VERSION "0.1"

NS_ :

BS_:

BU_: Broadcast CockpitECU HydrogenECU HighPowerECU SensorsECU CoolingECU IsolationECU DriverInterfaceHAT TelemetryLTEHAT

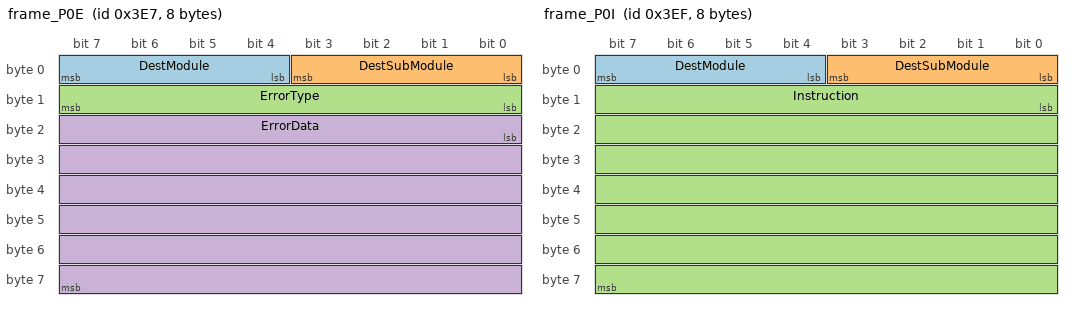
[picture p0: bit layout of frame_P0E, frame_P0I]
BO_ 999 frame_P0E: 8 Broadcast
	SG_ DestModule : 4|4@1+ (1,0) [0|0] "" Vector__XXX
	SG_ DestSubModule : 0|4@1+ (1,0) [0|0] "" Vector__XXX
	SG_ ErrorType : 8|8@1+ (1,0) [0|0] "" Vector__XXX
	SG_ ErrorData : 16|48@1+ (1,0) [0|0] "" Vector__XXX

BO_ 1007 frame_P0I: 8 Broadcast
	SG_ DestModule : 4|4@1+ (1,0) [0|0] "" Vector__XXX
	SG_ DestSubModule : 0|4@1+ (1,0) [0|0] "" Vector__XXX
	SG_ Instruction : 8|56@1+ (1,0) [0|0] "" Vector__XXX

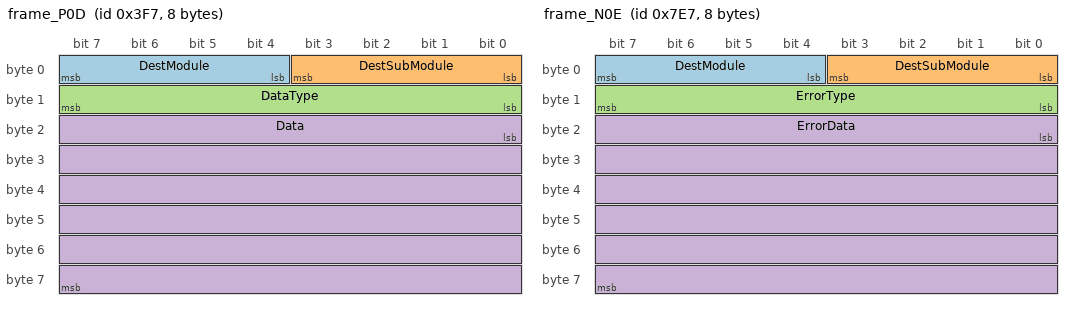
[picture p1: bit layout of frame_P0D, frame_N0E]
BO_ 1015 frame_P0D: 8 Broadcast
	SG_ DestModule : 4|4@1+ (1,0) [0|0] "" Vector__XXX
	SG_ DestSubModule : 0|4@1+ (1,0) [0|0] "" Vector__XXX
	SG_ DataType : 8|8@1+ (1,0) [0|0] "" Vector__XXX
	SG_ Data : 16|48@1+ (1,0) [0|0] "" Vector__XXX

BO_ 2023 frame_N0E: 8 Broadcast
	SG_ DestModule : 4|4@1+ (1,0) [0|0] "" Vector__XXX
	SG_ DestSubModule : 0|4@1+ (1,0) [0|0] "" Vector__XXX
	SG_ ErrorType : 8|8@1+ (1,0) [0|0] "" Vector__XXX
	SG_ ErrorData : 16|48@1+ (1,0) [0|0] "" Vector__XXX

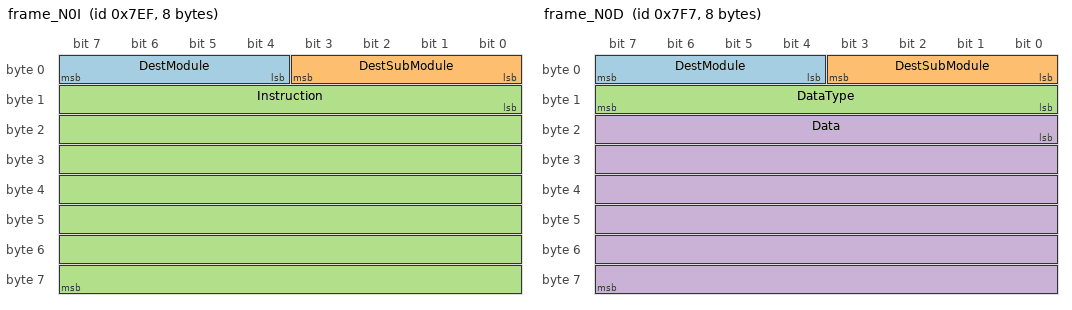
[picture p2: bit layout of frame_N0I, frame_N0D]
BO_ 2031 frame_N0I: 8 Broadcast
	SG_ DestModule : 4|4@1+ (1,0) [0|0] "" Vector__XXX
	SG_ DestSubModule : 0|4@1+ (1,0) [0|0] "" Vector__XXX
	SG_ Instruction : 8|56@1+ (1,0) [0|0] "" Vector__XXX

BO_ 2039 frame_N0D: 8 Broadcast
	SG_ DestModule : 4|4@1+ (1,0) [0|0] "" Vector__XXX
	SG_ DestSubModule : 0|4@1+ (1,0) [0|0] "" Vector__XXX
	SG_ DataType : 8|8@1+ (1,0) [0|0] "" Vector__XXX
	SG_ Data : 16|48@1+ (1,0) [0|0] "" Vector__XXX

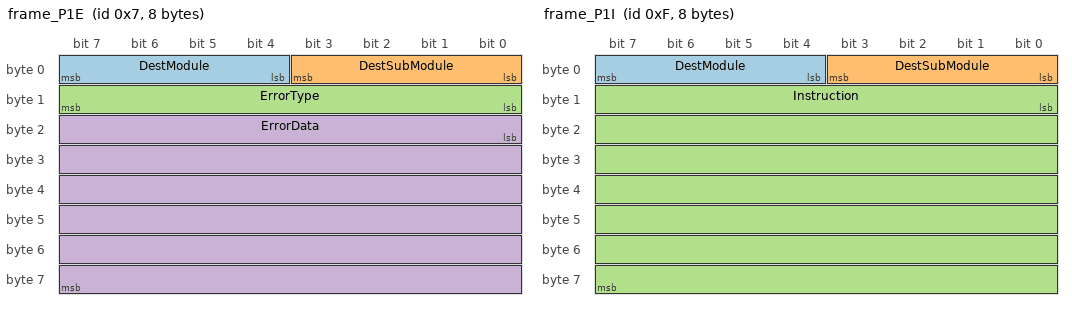
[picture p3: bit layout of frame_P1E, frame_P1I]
BO_ 7 frame_P1E: 8 CockpitECU
	SG_ DestModule : 4|4@1+ (1,0) [0|0] "" Vector__XXX
	SG_ DestSubModule : 0|4@1+ (1,0) [0|0] "" Vector__XXX
	SG_ ErrorType : 8|8@1+ (1,0) [0|0] "" Vector__XXX
	SG_ ErrorData : 16|48@1+ (1,0) [0|0] "" Vector__XXX

BO_ 15 frame_P1I: 8 CockpitECU
	SG_ DestModule : 4|4@1+ (1,0) [0|0] "" Vector__XXX
	SG_ DestSubModule : 0|4@1+ (1,0) [0|0] "" Vector__XXX
	SG_ Instruction : 8|56@1+ (1,0) [0|0] "" Vector__XXX

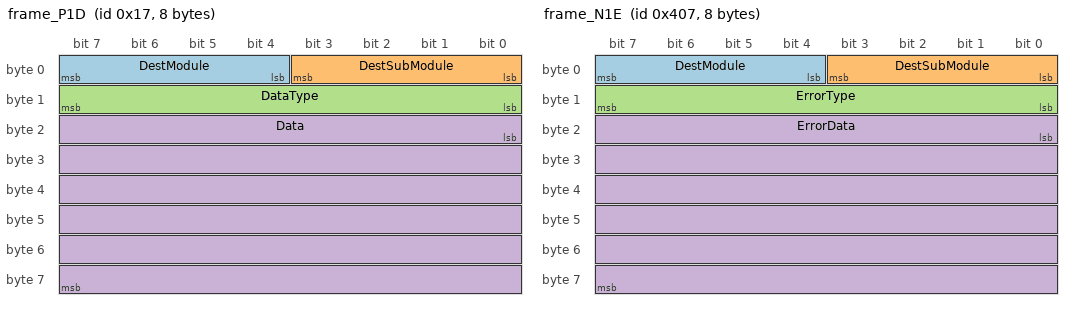
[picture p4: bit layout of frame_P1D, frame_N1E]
BO_ 23 frame_P1D: 8 CockpitECU
	SG_ DestModule : 4|4@1+ (1,0) [0|0] "" Vector__XXX
	SG_ DestSubModule : 0|4@1+ (1,0) [0|0] "" Vector__XXX
	SG_ DataType : 8|8@1+ (1,0) [0|0] "" Vector__XXX
	SG_ Data : 16|48@1+ (1,0) [0|0] "" Vector__XXX

BO_ 1031 frame_N1E: 8 CockpitECU
	SG_ DestModule : 4|4@1+ (1,0) [0|0] "" Vector__XXX
	SG_ DestSubModule : 0|4@1+ (1,0) [0|0] "" Vector__XXX
	SG_ ErrorType : 8|8@1+ (1,0) [0|0] "" Vector__XXX
	SG_ ErrorData : 16|48@1+ (1,0) [0|0] "" Vector__XXX

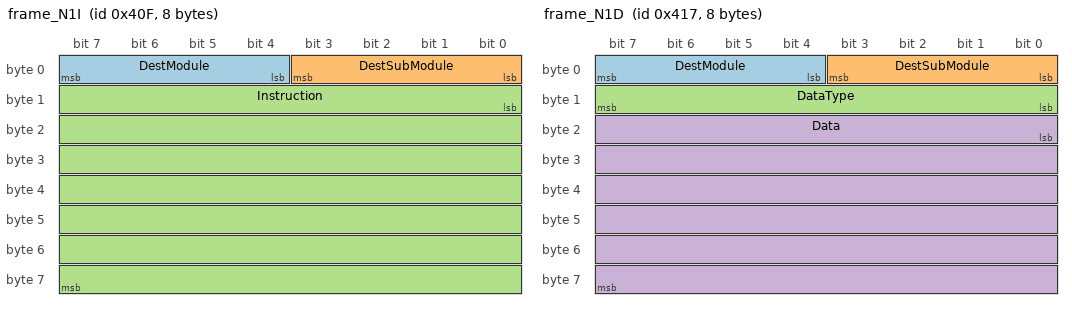
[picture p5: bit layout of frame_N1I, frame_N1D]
BO_ 1039 frame_N1I: 8 CockpitECU
	SG_ DestModule : 4|4@1+ (1,0) [0|0] "" Vector__XXX
	SG_ DestSubModule : 0|4@1+ (1,0) [0|0] "" Vector__XXX
	SG_ Instruction : 8|56@1+ (1,0) [0|0] "" Vector__XXX

BO_ 1047 frame_N1D: 8 CockpitECU
	SG_ DestModule : 4|4@1+ (1,0) [0|0] "" Vector__XXX
	SG_ DestSubModule : 0|4@1+ (1,0) [0|0] "" Vector__XXX
	SG_ DataType : 8|8@1+ (1,0) [0|0] "" Vector__XXX
	SG_ Data : 16|48@1+ (1,0) [0|0] "" Vector__XXX

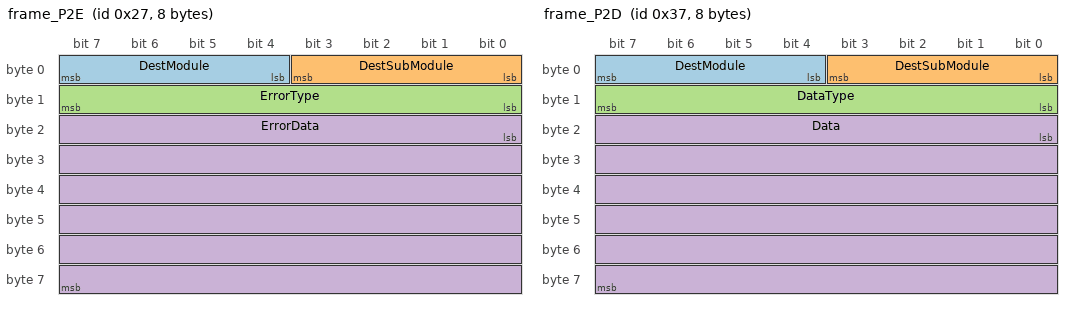
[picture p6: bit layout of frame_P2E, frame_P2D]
BO_ 39 frame_P2E: 8 HydrogenECU
	SG_ DestModule : 4|4@1+ (1,0) [0|0] "" Vector__XXX
	SG_ DestSubModule : 0|4@1+ (1,0) [0|0] "" Vector__XXX
	SG_ ErrorType : 8|8@1+ (1,0) [0|0] "" Vector__XXX
	SG_ ErrorData : 16|48@1+ (1,0) [0|0] "" Vector__XXX

BO_ 47 frame_P2I: 8 HydrogenECU
	SG_ DestModule : 4|4@1+ (1,0) [0|0] "" Vector__XXX
	SG_ DestSubModule : 0|4@1+ (1,0) [0|0] "" Vector__XXX
	SG_ Instruction : 8|56@1+ (1,0) [0|0] "" Vector__XXX

BO_ 55 frame_P2D: 8 HydrogenECU
	SG_ DestModule : 4|4@1+ (1,0) [0|0] "" Vector__XXX
	SG_ DestSubModule : 0|4@1+ (1,0) [0|0] "" Vector__XXX
	SG_ DataType : 8|8@1+ (1,0) [0|0] "" Vector__XXX
	SG_ Data : 16|48@1+ (1,0) [0|0] "" Vector__XXX

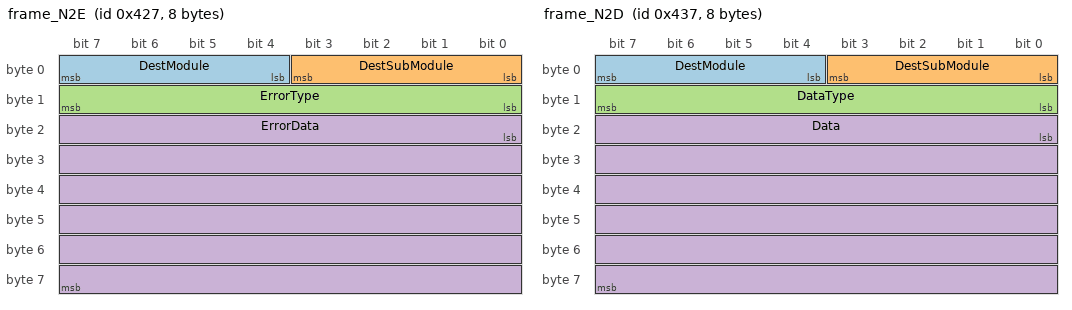
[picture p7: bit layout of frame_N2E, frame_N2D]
BO_ 1063 frame_N2E: 8 HydrogenECU
	SG_ DestModule : 4|4@1+ (1,0) [0|0] "" Vector__XXX
	SG_ DestSubModule : 0|4@1+ (1,0) [0|0] "" Vector__XXX
	SG_ ErrorType : 8|8@1+ (1,0) [0|0] "" Vector__XXX
	SG_ ErrorData : 16|48@1+ (1,0) [0|0] "" Vector__XXX

BO_ 1071 frame_N2I: 8 HydrogenECU
	SG_ DestModule : 4|4@1+ (1,0) [0|0] "" Vector__XXX
	SG_ DestSubModule : 0|4@1+ (1,0) [0|0] "" Vector__XXX
	SG_ Instruction : 8|56@1+ (1,0) [0|0] "" Vector__XXX

BO_ 1079 frame_N2D: 8 HydrogenECU
	SG_ DestModule : 4|4@1+ (1,0) [0|0] "" Vector__XXX
	SG_ DestSubModule : 0|4@1+ (1,0) [0|0] "" Vector__XXX
	SG_ DataType : 8|8@1+ (1,0) [0|0] "" Vector__XXX
	SG_ Data : 16|48@1+ (1,0) [0|0] "" Vector__XXX

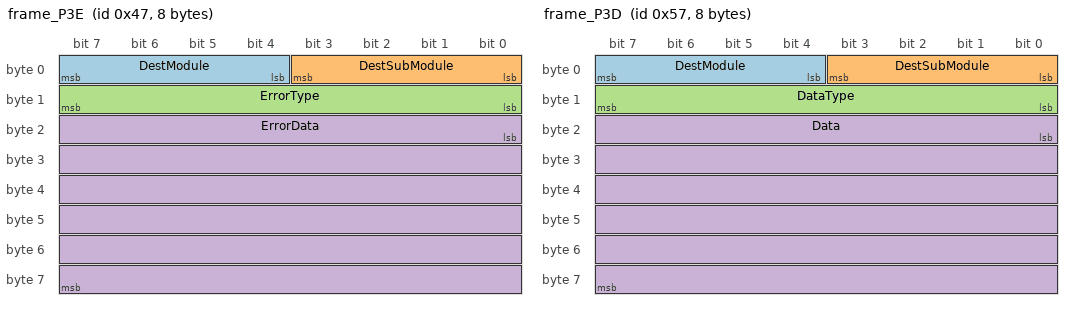
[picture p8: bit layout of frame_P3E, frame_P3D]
BO_ 71 frame_P3E: 8 HighPowerECU
	SG_ DestModule : 4|4@1+ (1,0) [0|0] "" Vector__XXX
	SG_ DestSubModule : 0|4@1+ (1,0) [0|0] "" Vector__XXX
	SG_ ErrorType : 8|8@1+ (1,0) [0|0] "" Vector__XXX
	SG_ ErrorData : 16|48@1+ (1,0) [0|0] "" Vector__XXX

BO_ 79 frame_P3I: 8 HighPowerECU
	SG_ DestModule : 4|4@1+ (1,0) [0|0] "" Vector__XXX
	SG_ DestSubModule : 0|4@1+ (1,0) [0|0] "" Vector__XXX
	SG_ Instruction : 8|56@1+ (1,0) [0|0] "" Vector__XXX

BO_ 87 frame_P3D: 8 HighPowerECU
	SG_ DestModule : 4|4@1+ (1,0) [0|0] "" Vector__XXX
	SG_ DestSubModule : 0|4@1+ (1,0) [0|0] "" Vector__XXX
	SG_ DataType : 8|8@1+ (1,0) [0|0] "" Vector__XXX
	SG_ Data : 16|48@1+ (1,0) [0|0] "" Vector__XXX

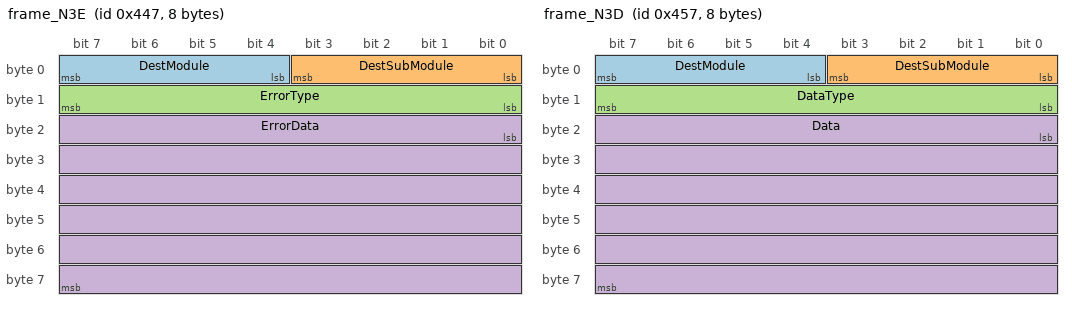
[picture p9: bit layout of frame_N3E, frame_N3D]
BO_ 1095 frame_N3E: 8 HighPowerECU
	SG_ DestModule : 4|4@1+ (1,0) [0|0] "" Vector__XXX
	SG_ DestSubModule : 0|4@1+ (1,0) [0|0] "" Vector__XXX
	SG_ ErrorType : 8|8@1+ (1,0) [0|0] "" Vector__XXX
	SG_ ErrorData : 16|48@1+ (1,0) [0|0] "" Vector__XXX

BO_ 1103 frame_N3I: 8 HighPowerECU
	SG_ DestModule : 4|4@1+ (1,0) [0|0] "" Vector__XXX
	SG_ DestSubModule : 0|4@1+ (1,0) [0|0] "" Vector__XXX
	SG_ Instruction : 8|56@1+ (1,0) [0|0] "" Vector__XXX

BO_ 1111 frame_N3D: 8 HighPowerECU
	SG_ DestModule : 4|4@1+ (1,0) [0|0] "" Vector__XXX
	SG_ DestSubModule : 0|4@1+ (1,0) [0|0] "" Vector__XXX
	SG_ DataType : 8|8@1+ (1,0) [0|0] "" Vector__XXX
	SG_ Data : 16|48@1+ (1,0) [0|0] "" Vector__XXX

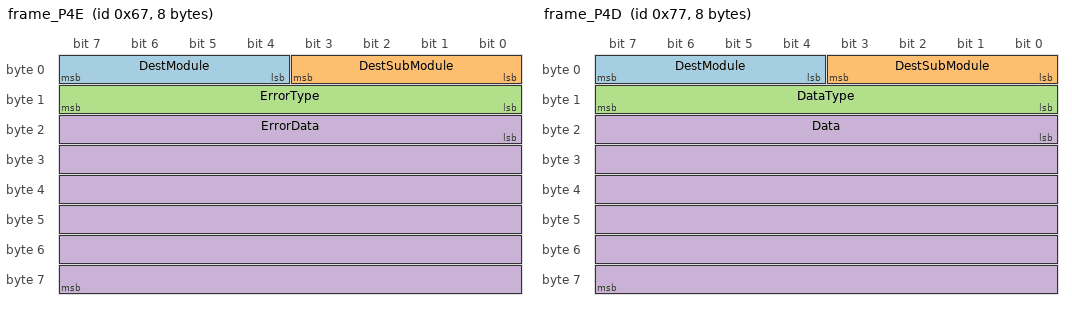
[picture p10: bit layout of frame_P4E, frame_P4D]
BO_ 103 frame_P4E: 8 SensorsECU
	SG_ DestModule : 4|4@1+ (1,0) [0|0] "" Vector__XXX
	SG_ DestSubModule : 0|4@1+ (1,0) [0|0] "" Vector__XXX
	SG_ ErrorType : 8|8@1+ (1,0) [0|0] "" Vector__XXX
	SG_ ErrorData : 16|48@1+ (1,0) [0|0] "" Vector__XXX

BO_ 111 frame_P4I: 8 SensorsECU
	SG_ DestModule : 4|4@1+ (1,0) [0|0] "" Vector__XXX
	SG_ DestSubModule : 0|4@1+ (1,0) [0|0] "" Vector__XXX
	SG_ Instruction : 8|56@1+ (1,0) [0|0] "" Vector__XXX

BO_ 119 frame_P4D: 8 SensorsECU
	SG_ DestModule : 4|4@1+ (1,0) [0|0] "" Vector__XXX
	SG_ DestSubModule : 0|4@1+ (1,0) [0|0] "" Vector__XXX
	SG_ DataType : 8|8@1+ (1,0) [0|0] "" Vector__XXX
	SG_ Data : 16|48@1+ (1,0) [0|0] "" Vector__XXX

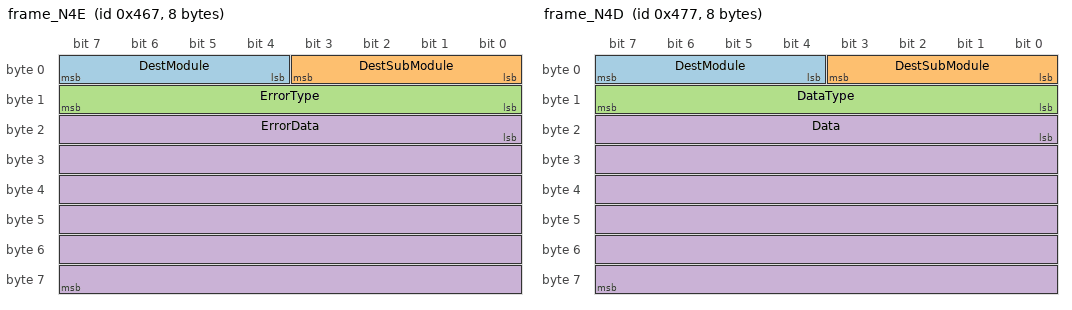
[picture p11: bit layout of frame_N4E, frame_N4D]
BO_ 1127 frame_N4E: 8 SensorsECU
	SG_ DestModule : 4|4@1+ (1,0) [0|0] "" Vector__XXX
	SG_ DestSubModule : 0|4@1+ (1,0) [0|0] "" Vector__XXX
	SG_ ErrorType : 8|8@1+ (1,0) [0|0] "" Vector__XXX
	SG_ ErrorData : 16|48@1+ (1,0) [0|0] "" Vector__XXX

BO_ 1135 frame_N4I: 8 SensorsECU
	SG_ DestModule : 4|4@1+ (1,0) [0|0] "" Vector__XXX
	SG_ DestSubModule : 0|4@1+ (1,0) [0|0] "" Vector__XXX
	SG_ Instruction : 8|56@1+ (1,0) [0|0] "" Vector__XXX

BO_ 1143 frame_N4D: 8 SensorsECU
	SG_ DestModule : 4|4@1+ (1,0) [0|0] "" Vector__XXX
	SG_ DestSubModule : 0|4@1+ (1,0) [0|0] "" Vector__XXX
	SG_ DataType : 8|8@1+ (1,0) [0|0] "" Vector__XXX
	SG_ Data : 16|48@1+ (1,0) [0|0] "" Vector__XXX

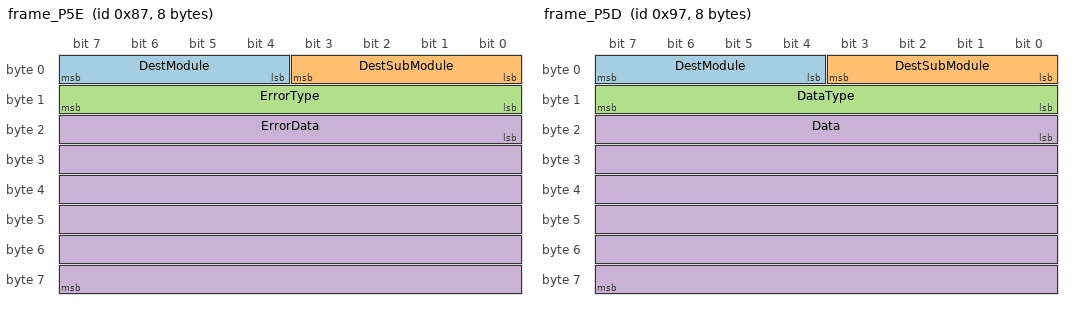
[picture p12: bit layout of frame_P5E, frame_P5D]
BO_ 135 frame_P5E: 8 CoolingECU
	SG_ DestModule : 4|4@1+ (1,0) [0|0] "" Vector__XXX
	SG_ DestSubModule : 0|4@1+ (1,0) [0|0] "" Vector__XXX
	SG_ ErrorType : 8|8@1+ (1,0) [0|0] "" Vector__XXX
	SG_ ErrorData : 16|48@1+ (1,0) [0|0] "" Vector__XXX

BO_ 143 frame_P5I: 8 CoolingECU
	SG_ DestModule : 4|4@1+ (1,0) [0|0] "" Vector__XXX
	SG_ DestSubModule : 0|4@1+ (1,0) [0|0] "" Vector__XXX
	SG_ Instruction : 8|56@1+ (1,0) [0|0] "" Vector__XXX

BO_ 151 frame_P5D: 8 CoolingECU
	SG_ DestModule : 4|4@1+ (1,0) [0|0] "" Vector__XXX
	SG_ DestSubModule : 0|4@1+ (1,0) [0|0] "" Vector__XXX
	SG_ DataType : 8|8@1+ (1,0) [0|0] "" Vector__XXX
	SG_ Data : 16|48@1+ (1,0) [0|0] "" Vector__XXX

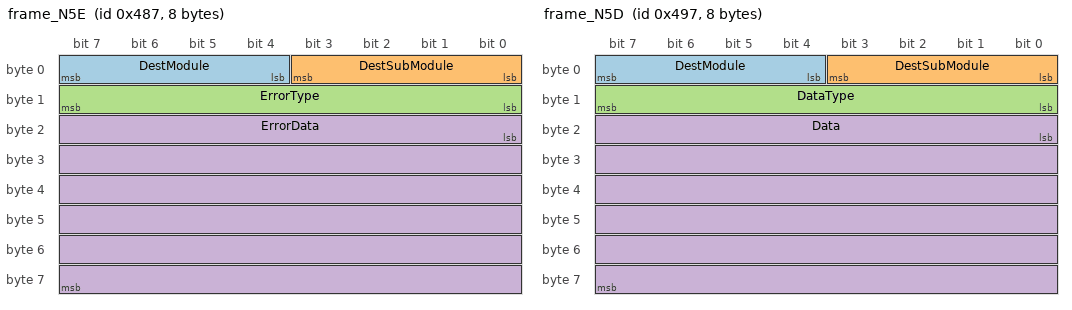
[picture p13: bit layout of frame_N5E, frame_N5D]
BO_ 1159 frame_N5E: 8 CoolingECU
	SG_ DestModule : 4|4@1+ (1,0) [0|0] "" Vector__XXX
	SG_ DestSubModule : 0|4@1+ (1,0) [0|0] "" Vector__XXX
	SG_ ErrorType : 8|8@1+ (1,0) [0|0] "" Vector__XXX
	SG_ ErrorData : 16|48@1+ (1,0) [0|0] "" Vector__XXX

BO_ 1167 frame_N5I: 8 CoolingECU
	SG_ DestModule : 4|4@1+ (1,0) [0|0] "" Vector__XXX
	SG_ DestSubModule : 0|4@1+ (1,0) [0|0] "" Vector__XXX
	SG_ Instruction : 8|56@1+ (1,0) [0|0] "" Vector__XXX

BO_ 1175 frame_N5D: 8 CoolingECU
	SG_ DestModule : 4|4@1+ (1,0) [0|0] "" Vector__XXX
	SG_ DestSubModule : 0|4@1+ (1,0) [0|0] "" Vector__XXX
	SG_ DataType : 8|8@1+ (1,0) [0|0] "" Vector__XXX
	SG_ Data : 16|48@1+ (1,0) [0|0] "" Vector__XXX

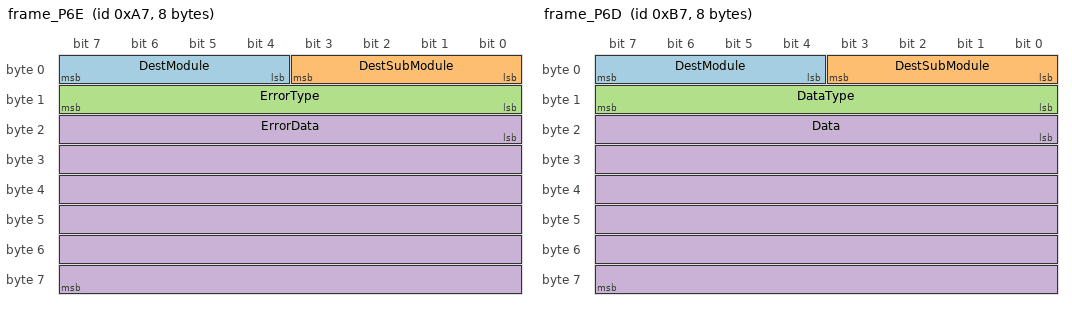
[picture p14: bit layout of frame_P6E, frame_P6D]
BO_ 167 frame_P6E: 8 IsolationECU
	SG_ DestModule : 4|4@1+ (1,0) [0|0] "" Vector__XXX
	SG_ DestSubModule : 0|4@1+ (1,0) [0|0] "" Vector__XXX
	SG_ ErrorType : 8|8@1+ (1,0) [0|0] "" Vector__XXX
	SG_ ErrorData : 16|48@1+ (1,0) [0|0] "" Vector__XXX

BO_ 175 frame_P6I: 8 IsolationECU
	SG_ DestModule : 4|4@1+ (1,0) [0|0] "" Vector__XXX
	SG_ DestSubModule : 0|4@1+ (1,0) [0|0] "" Vector__XXX
	SG_ Instruction : 8|56@1+ (1,0) [0|0] "" Vector__XXX

BO_ 183 frame_P6D: 8 IsolationECU
	SG_ DestModule : 4|4@1+ (1,0) [0|0] "" Vector__XXX
	SG_ DestSubModule : 0|4@1+ (1,0) [0|0] "" Vector__XXX
	SG_ DataType : 8|8@1+ (1,0) [0|0] "" Vector__XXX
	SG_ Data : 16|48@1+ (1,0) [0|0] "" Vector__XXX

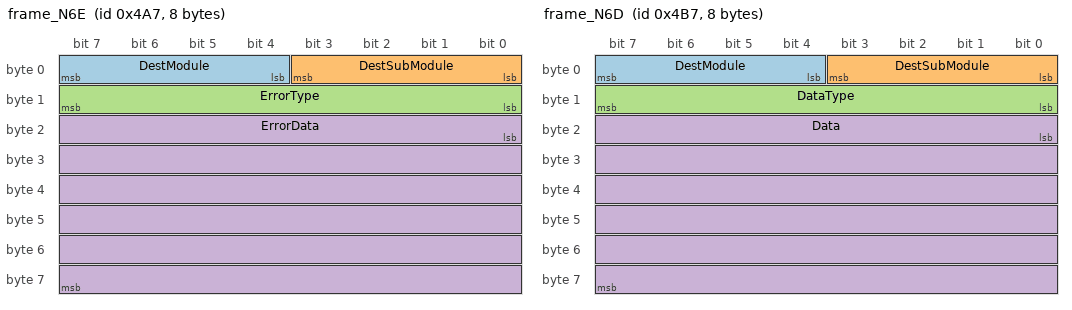
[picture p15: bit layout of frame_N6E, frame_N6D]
BO_ 1191 frame_N6E: 8 IsolationECU
	SG_ DestModule : 4|4@1+ (1,0) [0|0] "" Vector__XXX
	SG_ DestSubModule : 0|4@1+ (1,0) [0|0] "" Vector__XXX
	SG_ ErrorType : 8|8@1+ (1,0) [0|0] "" Vector__XXX
	SG_ ErrorData : 16|48@1+ (1,0) [0|0] "" Vector__XXX

BO_ 1199 frame_N6I: 8 IsolationECU
	SG_ DestModule : 4|4@1+ (1,0) [0|0] "" Vector__XXX
	SG_ DestSubModule : 0|4@1+ (1,0) [0|0] "" Vector__XXX
	SG_ Instruction : 8|56@1+ (1,0) [0|0] "" Vector__XXX

BO_ 1207 frame_N6D: 8 IsolationECU
	SG_ DestModule : 4|4@1+ (1,0) [0|0] "" Vector__XXX
	SG_ DestSubModule : 0|4@1+ (1,0) [0|0] "" Vector__XXX
	SG_ DataType : 8|8@1+ (1,0) [0|0] "" Vector__XXX
	SG_ Data : 16|48@1+ (1,0) [0|0] "" Vector__XXX

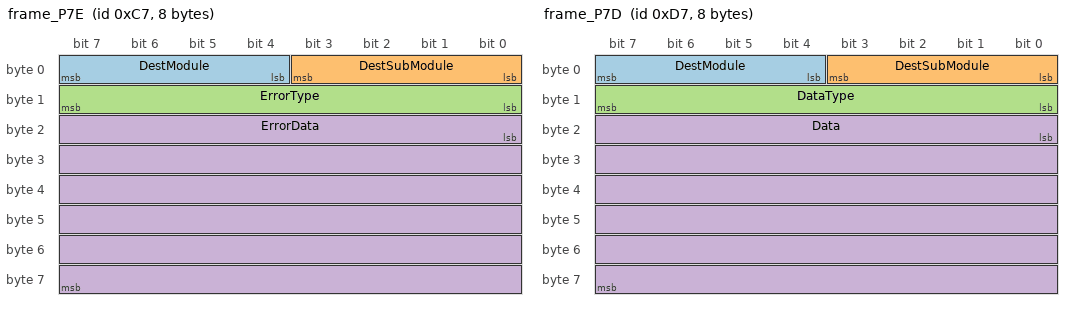
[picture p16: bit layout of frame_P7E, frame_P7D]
BO_ 199 frame_P7E: 8 DriverInterfaceHAT
	SG_ DestModule : 4|4@1+ (1,0) [0|0] "" Vector__XXX
	SG_ DestSubModule : 0|4@1+ (1,0) [0|0] "" Vector__XXX
	SG_ ErrorType : 8|8@1+ (1,0) [0|0] "" Vector__XXX
	SG_ ErrorData : 16|48@1+ (1,0) [0|0] "" Vector__XXX

BO_ 207 frame_P7I: 8 DriverInterfaceHAT
	SG_ DestModule : 4|4@1+ (1,0) [0|0] "" Vector__XXX
	SG_ DestSubModule : 0|4@1+ (1,0) [0|0] "" Vector__XXX
	SG_ Instruction : 8|56@1+ (1,0) [0|0] "" Vector__XXX

BO_ 215 frame_P7D: 8 DriverInterfaceHAT
	SG_ DestModule : 4|4@1+ (1,0) [0|0] "" Vector__XXX
	SG_ DestSubModule : 0|4@1+ (1,0) [0|0] "" Vector__XXX
	SG_ DataType : 8|8@1+ (1,0) [0|0] "" Vector__XXX
	SG_ Data : 16|48@1+ (1,0) [0|0] "" Vector__XXX

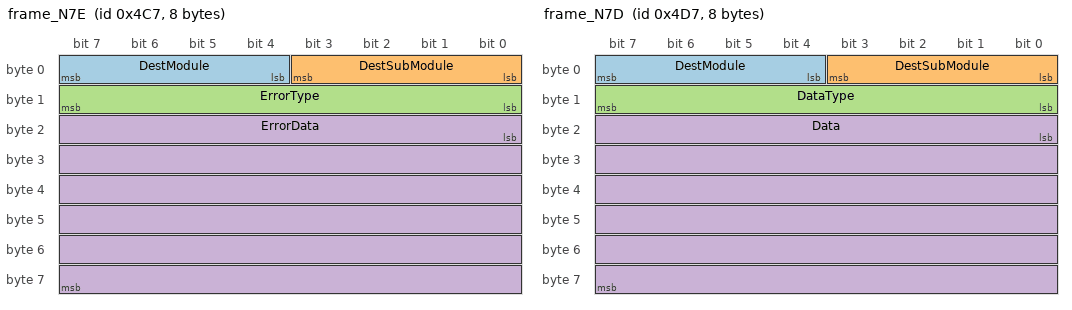
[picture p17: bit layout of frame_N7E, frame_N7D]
BO_ 1223 frame_N7E: 8 DriverInterfaceHAT
	SG_ DestModule : 4|4@1+ (1,0) [0|0] "" Vector__XXX
	SG_ DestSubModule : 0|4@1+ (1,0) [0|0] "" Vector__XXX
	SG_ ErrorType : 8|8@1+ (1,0) [0|0] "" Vector__XXX
	SG_ ErrorData : 16|48@1+ (1,0) [0|0] "" Vector__XXX

BO_ 1231 frame_N7I: 8 DriverInterfaceHAT
	SG_ DestModule : 4|4@1+ (1,0) [0|0] "" Vector__XXX
	SG_ DestSubModule : 0|4@1+ (1,0) [0|0] "" Vector__XXX
	SG_ Instruction : 8|56@1+ (1,0) [0|0] "" Vector__XXX

BO_ 1239 frame_N7D: 8 DriverInterfaceHAT
	SG_ DestModule : 4|4@1+ (1,0) [0|0] "" Vector__XXX
	SG_ DestSubModule : 0|4@1+ (1,0) [0|0] "" Vector__XXX
	SG_ DataType : 8|8@1+ (1,0) [0|0] "" Vector__XXX
	SG_ Data : 16|48@1+ (1,0) [0|0] "" Vector__XXX

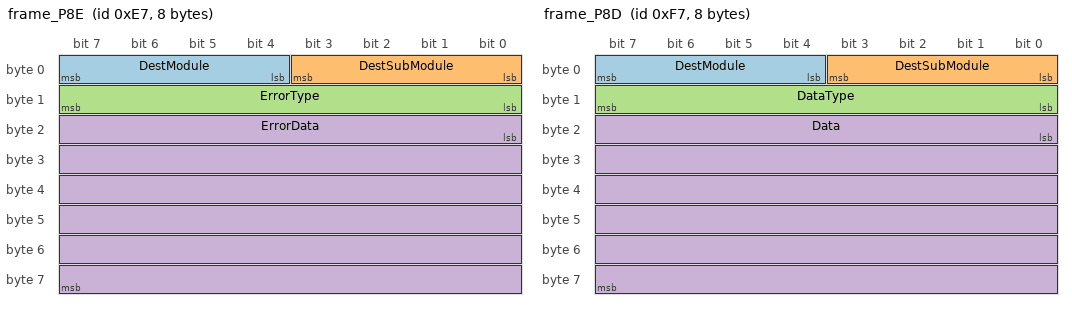
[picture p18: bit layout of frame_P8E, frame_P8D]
BO_ 231 frame_P8E: 8 TelemetryLTEHAT
	SG_ DestModule : 4|4@1+ (1,0) [0|0] "" Vector__XXX
	SG_ DestSubModule : 0|4@1+ (1,0) [0|0] "" Vector__XXX
	SG_ ErrorType : 8|8@1+ (1,0) [0|0] "" Vector__XXX
	SG_ ErrorData : 16|48@1+ (1,0) [0|0] "" Vector__XXX

BO_ 239 frame_P8I: 8 TelemetryLTEHAT
	SG_ DestModule : 4|4@1+ (1,0) [0|0] "" Vector__XXX
	SG_ DestSubModule : 0|4@1+ (1,0) [0|0] "" Vector__XXX
	SG_ Instruction : 8|56@1+ (1,0) [0|0] "" Vector__XXX

BO_ 247 frame_P8D: 8 TelemetryLTEHAT
	SG_ DestModule : 4|4@1+ (1,0) [0|0] "" Vector__XXX
	SG_ DestSubModule : 0|4@1+ (1,0) [0|0] "" Vector__XXX
	SG_ DataType : 8|8@1+ (1,0) [0|0] "" Vector__XXX
	SG_ Data : 16|48@1+ (1,0) [0|0] "" Vector__XXX

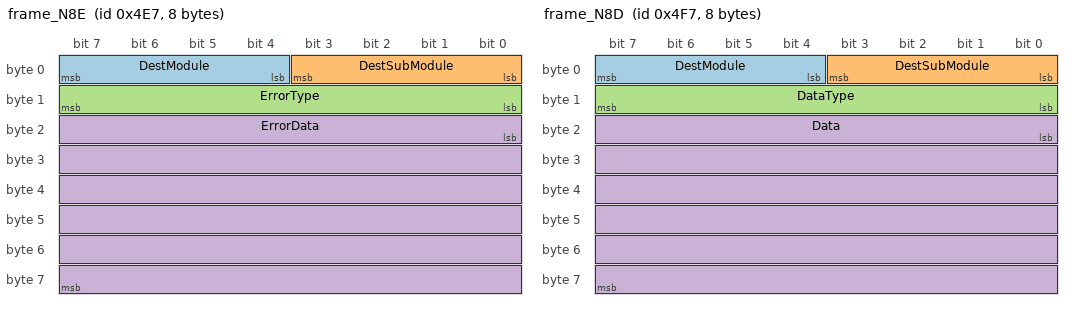
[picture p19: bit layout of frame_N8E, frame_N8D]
BO_ 1255 frame_N8E: 8 TelemetryLTEHAT
	SG_ DestModule : 4|4@1+ (1,0) [0|0] "" Vector__XXX
	SG_ DestSubModule : 0|4@1+ (1,0) [0|0] "" Vector__XXX
	SG_ ErrorType : 8|8@1+ (1,0) [0|0] "" Vector__XXX
	SG_ ErrorData : 16|48@1+ (1,0) [0|0] "" Vector__XXX

BO_ 1263 frame_N8I: 8 TelemetryLTEHAT
	SG_ DestModule : 4|4@1+ (1,0) [0|0] "" Vector__XXX
	SG_ DestSubModule : 0|4@1+ (1,0) [0|0] "" Vector__XXX
	SG_ Instruction : 8|56@1+ (1,0) [0|0] "" Vector__XXX

BO_ 1271 frame_N8D: 8 TelemetryLTEHAT
	SG_ DestModule : 4|4@1+ (1,0) [0|0] "" Vector__XXX
	SG_ DestSubModule : 0|4@1+ (1,0) [0|0] "" Vector__XXX
	SG_ DataType : 8|8@1+ (1,0) [0|0] "" Vector__XXX
	SG_ Data : 16|48@1+ (1,0) [0|0] "" Vector__XXX

BO_ 250 Nci: 8 CockpitECU
	SG_ DestModule : 4|4@1+ (1,0) [0|0] "" Vector__XXX
	SG_ DestSubModule : 0|4@1+ (1,0) [0|0] "" Vector__XXX
	SG_ Instruction : 8|32@1+ (1,0) [0|0] "" Vector__XXX
